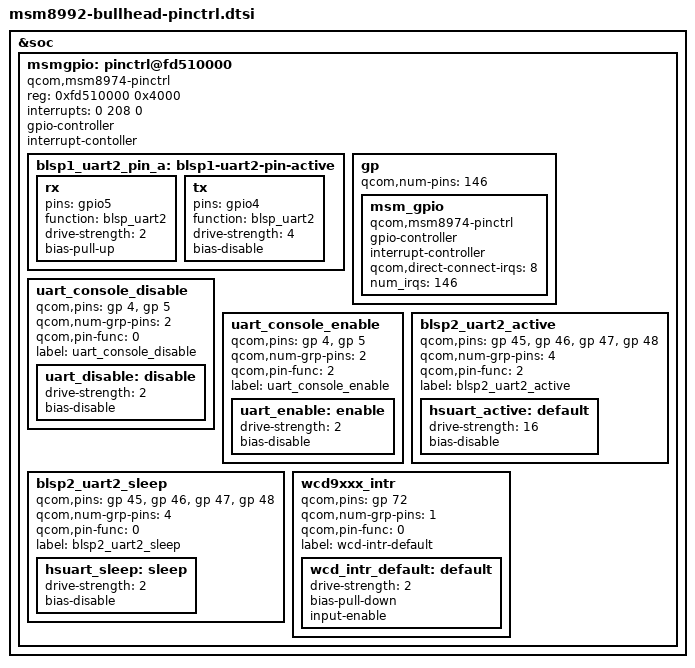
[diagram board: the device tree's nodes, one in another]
/* Copyright (c) 2015, LGE Inc. All rights reserved.
 * Copyright (c) 2013-2015, The Linux Foundation. All rights reserved.
 *
 * This program is free software; you can redistribute it and/or modify
 * it under the terms of the GNU General Public License version 2 and
 * only version 2 as published by the Free Software Foundation.
 *
 * This program is distributed in the hope that it will be useful,
 * but WITHOUT ANY WARRANTY; without even the implied warranty of
 * MERCHANTABILITY or FITNESS FOR A PARTICULAR PURPOSE.  See the
 * GNU General Public License for more details.
 */

&soc {
	msmgpio: pinctrl@fd510000 {
		compatible = "qcom,msm8974-pinctrl";
		reg = <0xfd510000 0x4000>;
		interrupts = <0 208 0>;
		gpio-controller;
		#gpio-cells = <2>;
		#interrupt-cells = <2>;
		interrupt-contoller;

                blsp1_uart2_pin_a: blsp1-uart2-pin-active {
                        rx {
                                pins = "gpio5";
                                function = "blsp_uart2";

                                drive-strength = <2>;
                                bias-pull-up;
                        };

                        tx {
                                pins = "gpio4";
                                function = "blsp_uart2";

                                drive-strength = <4>;
                                bias-disable;
                        };
                };

		/*General purpose pins*/
		gp: gp {
			qcom,num-pins = <146>;
			#qcom,pin-cells = <1>;

			msm_gpio: msm_gpio {
				compatible = "qcom,msm8974-pinctrl";
				gpio-controller;
				#gpio-cells = <2>;
				interrupt-controller;
				#interrupt-cells = <2>;
				qcom,direct-connect-irqs = <8>;
				num_irqs = <146>;
				pinctrl-names = "default";
			};
		};

		uart_console_disable {
			qcom,pins = <&gp 4>, <&gp 5>;
			qcom,num-grp-pins = <2>;
			qcom,pin-func = <0>;
			label = "uart_console_disable";
			uart_disable: disable {
				drive-strength = <2>;
				bias-disable;
			};
		};

		uart_console_enable {
			qcom,pins = <&gp 4>, <&gp 5>;
			qcom,num-grp-pins = <2>;
			qcom,pin-func = <2>;
			label = "uart_console_enable";
			uart_enable: enable {
				drive-strength = <2>;
				bias-disable;
			};
		};

		blsp2_uart2_active {
			qcom,pins = <&gp 45>, <&gp 46>, <&gp 47>, <&gp 48>;
			qcom,num-grp-pins = <4>;
			qcom,pin-func = <2>;
		        label = "blsp2_uart2_active";
			hsuart_active: default {
				drive-strength = <16>;
				bias-disable;
			};
		};

		blsp2_uart2_sleep {
			qcom,pins = <&gp 45>, <&gp 46>, <&gp 47>, <&gp 48>;
			qcom,num-grp-pins = <4>;
			qcom,pin-func = <0>;
		        label = "blsp2_uart2_sleep";
			hsuart_sleep: sleep {
				drive-strength = <2>;
				bias-disable;
			};
		};

		wcd9xxx_intr {
			qcom,pins = <&gp 72>;
			qcom,num-grp-pins = <1>;
			qcom,pin-func = <0>;
			label = "wcd-intr-default";
			wcd_intr_default: default {
				drive-strength = <2>;
				bias-pull-down;
				input-enable;
			};
		};

	};
};
